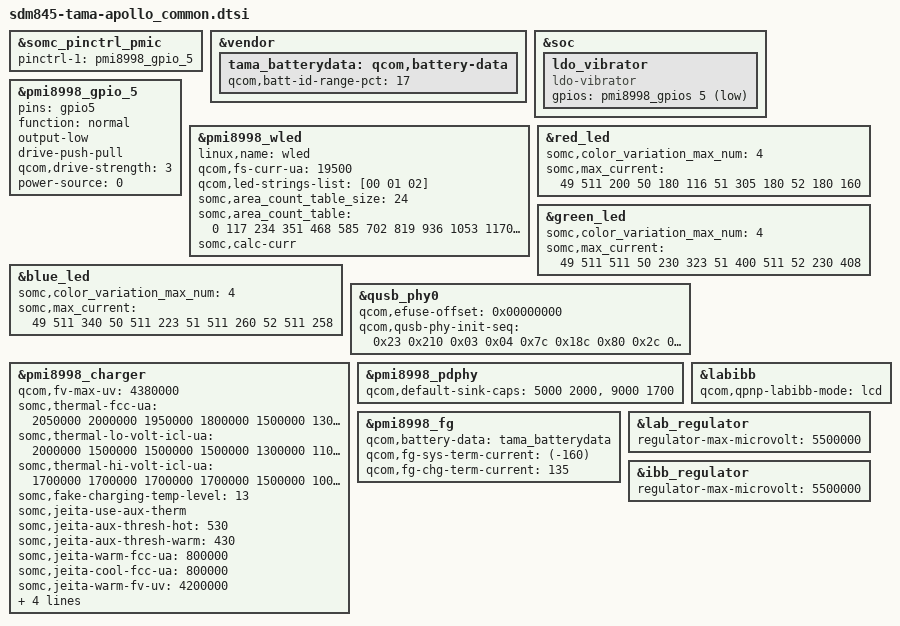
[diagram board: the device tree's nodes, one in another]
/* arch/arm64/boot/dts/somc/sdm845-tama-apollo_common.dtsi
 *
 * This program is free software; you can redistribute it and/or modify
 * it under the terms of the GNU General Public License version 2 and
 * only version 2 as published by the Free Software Foundation.
 *
 * This program is distributed in the hope that it will be useful,
 * but WITHOUT ANY WARRANTY; without even the implied warranty of
 * MERCHANTABILITY or FITNESS FOR A PARTICULAR PURPOSE.  See the
 * GNU General Public License for more details.
 */
/*
 * Copyright (C) 2017 Sony Mobile Communications Inc.
 *
 * This program is free software; you can redistribute it and/or modify
 * it under the terms of the GNU General Public License version 2, as
 * published by the Free Software Foundation.
 */

#include "sdm845-tama-common.dtsi"
#include "sdm845-tama-common-display.dtsi"
#include "sdm845-tama-akari-camera.dtsi"
#include "dsi-panel-somc-apollo.dtsi"

&somc_pinctrl_pmic {
	pinctrl-1 = <&pmi8998_gpio_5>;
};

&vendor {
	tama_batterydata: qcom,battery-data {
		qcom,batt-id-range-pct = <17>;
		#include "fg-gen3-batterydata-apollo-tmm-4380mv.dtsi"
		#include "fg-gen3-batterydata-apollo-tmm-4340mv.dtsi"
		#include "fg-gen3-batterydata-apollo-tmm-4300mv.dtsi"
		#include "fg-gen3-batterydata-apollo-tmm-4250mv.dtsi"
	};
};

&soc {
	ldo_vibrator {
		compatible = "ldo-vibrator";
		gpios = <&pmi8998_gpios 5 1>;
	};
};

/* GPIO_5: VIB_LDO_EN */
&pmi8998_gpio_5 {
	pins = "gpio5";
	function = "normal";
	/delete-property/ bias-high-impedance;
	output-low;
	drive-push-pull;
	qcom,drive-strength = <3>;
	power-source = <0>;
};

&pmi8998_wled {
	linux,name = "wled";
	qcom,fs-curr-ua = <19500>;
	qcom,led-strings-list = [00 01 02];
	somc,area_count_table_size = <24>;
	somc,area_count_table = <0 117 234 351 468 585 702 819
				936 1053 1170 1404 1638 1872 2106
				2340 2574 2808 3042 3276 3510
				3744 3978 4095>;
	somc,calc-curr;
};

&red_led {
	somc,color_variation_max_num = <4>;
	somc,max_current = <
		49 511 200
		50 180 116
		51 305 180
		52 180 160>;
};

&green_led {
	somc,color_variation_max_num = <4>;
	somc,max_current = <
		49 511 511
		50 230 323
		51 400 511
		52 230 408>;
};

&blue_led {
	somc,color_variation_max_num = <4>;
	somc,max_current = <
		49 511 340
		50 511 223
		51 511 260
		52 511 258>;
};

&qusb_phy0 {
	qcom,efuse-offset = <0x00000000>;
	qcom,qusb-phy-init-seq =
		/* <value reg_offset> */
		   <0x23 0x210 /* PWR_CTRL1 */
		    0x03 0x04  /* PLL_ANALOG_CONTROLS_TWO */
		    0x7c 0x18c /* PLL_CLOCK_INVERTERS */
		    0x80 0x2c  /* PLL_CMODE */
		    0x0a 0x184 /* PLL_LOCK_DELAY */
		    0x19 0xb4  /* PLL_DIGITAL_TIMERS_TWO */
		    0x40 0x194 /* PLL_BIAS_CONTROL_1 */
		    0x1a 0x198 /* PLL_BIAS_CONTROL_2 */
		    0x21 0x214 /* PWR_CTRL2 */
		    0x08 0x220 /* IMP_CTRL1 */
		    0x58 0x224 /* IMP_CTRL2 */
		    0x71 0x240 /* TUNE1 */
		    0x2B 0x244 /* TUNE2 */
		    0xca 0x248 /* TUNE3 */
		    0x04 0x24c /* TUNE4 */
		    0x01 0x250 /* TUNE5 */
		    0x00 0x23c /* CHG_CTRL2 */
		    0x22 0x210>; /* PWR_CTRL1 */
};

&pmi8998_charger {
	qcom,fv-max-uv = <4380000>;
	somc,thermal-fcc-ua = <2050000 2000000 1950000
				1800000 1500000 1300000
				1300000 1000000 800000
				700000 500000 200000
				100000 0 0>;
	somc,thermal-lo-volt-icl-ua = <2000000 1500000 1500000
					1500000 1300000 1100000
					1100000 1000000 900000
					900000 500000 200000
					100000 0 0>;
	somc,thermal-hi-volt-icl-ua = <1700000 1700000 1700000
					1700000 1500000 1000000
					1000000 1000000 1000000
					600000 500000 200000
					100000 0 0>;
	somc,fake-charging-temp-level = <13>;
	somc,jeita-use-aux-therm;
	somc,jeita-aux-thresh-hot = <530>;
	somc,jeita-aux-thresh-warm = <430>;
	somc,jeita-warm-fcc-ua = <800000>;
	somc,jeita-cool-fcc-ua = <800000>;
	somc,jeita-warm-fv-uv = <4200000>;
	somc,product-icl-ua = <2000000>;
	somc,high-voltage-icl-ua = <1700000>;
	somc,batt-temp-correction = <0>;
	somc,skin-temp-correction = <20>;
};

&pmi8998_pdphy {
	qcom,default-sink-caps = <5000 2000>, /* 5V @ 2A */
				 <9000 1700>; /* 9V @ 1.7A */
};

&pmi8998_fg {
	qcom,battery-data = <&tama_batterydata>;
	qcom,fg-sys-term-current = <(-160)>;
	qcom,fg-chg-term-current = <135>;
};

&labibb {
	qcom,qpnp-labibb-mode = "lcd";
};

&lab_regulator {
	regulator-max-microvolt = <5500000>;
};

&ibb_regulator {
	regulator-max-microvolt = <5500000>;
};
